# MSS_ETPWM3 register map
Vendor: Texas Instruments
Peripheral module from a debugger description file (folder radar).
Registers are 32-bit, read-write, no defined reset value unless marked. A register's access mark holds for its fields unless they carry their own. Offsets are as the file gives them; lines under a group give offsets from that group; [hi:lo] are bit positions; {n}, {i} and the like mark numbered series; 'fields as' and 'values as' point back to an identical list; <NAME> marks a mode.

## MSS_ETPWM3
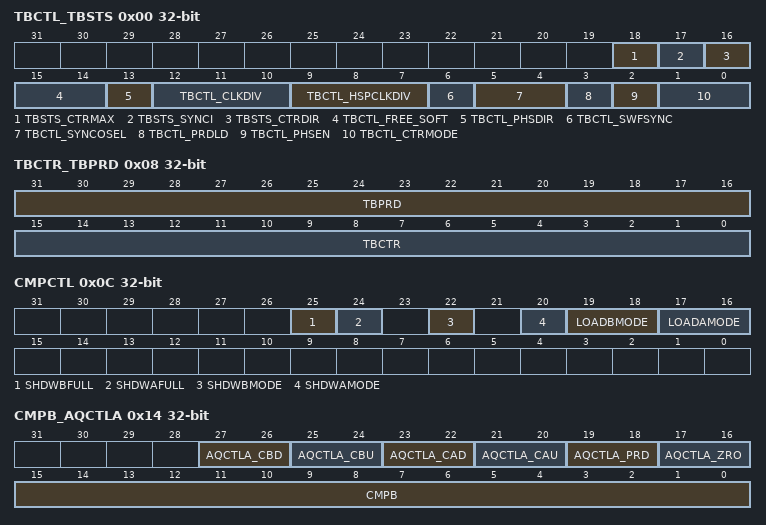
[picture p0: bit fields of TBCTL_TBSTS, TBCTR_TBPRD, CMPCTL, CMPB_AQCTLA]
0x00 TBCTL_TBSTS — Time-Base Control Register/ Status Register
  [18] TBSTS_CTRMAX — Time-Base Counter Max Latched Status Bit 0 Read: Indicates the time-base counter never reached its maximum value. Write: No effect. 1 Read: Indicates that the time-base counter reached the maximum value 0xFFFF. Write: Clears the latched event.
  [17] TBSTS_SYNCI — Input Synchronization Latched Status Bit 0 Read: Indicates no external synchronization event has occurred. Write: No effect. 1 Read: Indicates that an external synchronization event has occurred (EPWMxSYNCI). Write: Clears the latched event.
  [16] TBSTS_CTRDIR — Time-Base Counter Direction Status Bit. At reset, the counter is frozen; therefore, this bit has no meaning. To make this bit meaningful, you must first set the appropriate mode via TBCTL[CTRMODE]. 0 Time-Base Counter is currently counting down. 1 Time-Base Counter is currently counting up.
  [15:14] TBCTL_FREE_SOFT — Emulation Mode Bits. These bits select the behavior of the ePWM time-base counter during emulation events: 0 Stop after the next time-base counter increment or decrement 1h Stop when counter completes a whole cycle: • Up-count mode: stop when the time-base counter = period (TBCTR = TBPRD) • Down-count mode: stop when the time-base counter = 0x0000 (TBCTR = 0x0000) • Up-down-count mode: stop when the time-base counter = 0x0000 (TBCTR = 0x0000) 2h-3h Free run
  [13] TBCTL_PHSDIR — Phase Direction Bit. This bit is only used when the time-base counter is configured in the up-down-count mode. The PHSDIR bit indicates the direction the time-base counter (TBCTR) will count after a synchronization event occurs and a new phase value is loaded from the phase (TBPHS) register. This is irrespective of the direction of the counter before the synchronization event.. In the up-count and down-count modes this bit is ignored. 0 Count down after the synchronization event. 1 Count up after the synchronization event
  [12:10] TBCTL_CLKDIV — Time-base Clock Prescale Bits These bits determine part of the time-base clock prescale value. TBCLK = VCLK3 / (HSPCLKDIV � CLKDIV) 0 /1 (default on reset) 1h /2 2h /4 3h /8 4h /16 5h /32 6h /64 7h /128
  [9:7] TBCTL_HSPCLKDIV — High Speed Time-base Clock Prescale Bits. These bits determine part of the time-base clock prescale value: TBCLK = VCLK3 / (HSPCLKDIV � CLKDIV) 0 /1 1h /2 (default on reset) 2h /4 3h /6 4h /8 5h /10 6h /12 7h /14
  [6] TBCTL_SWFSYNC — Software Forced Synchronization Pulse 0 Writing a 0 has no effect and reads always return a 0. 1 Writing a 1 forces a one-time synchronization pulse to be generated. This event is ORed with the EPWMxSYNCI input of the ePWM module. SWFSYNC is valid (operates) only when EPWMxSYNCI is selected by SYNCOSEL = 00.
  [5:4] TBCTL_SYNCOSEL — Synchronization Output Select. These bits select the source of the EPWMxSYNCO signal. 0 EPWMxSYNC: 1h CTR = zero: Time-base counter equal to zero (TBCTR = 0x0000) 2h CTR = CMPB : Time-base counter equal to counter-compare B (TBCTR = CMPB) 3h Disable EPWMxSYNCO signal
  [3] TBCTL_PRDLD — Active Period Register Load From Shadow Register Select 0 The period register (TBPRD) is loaded from its shadow register when the time-base counter, TBCTR, is equal to zero. A write or read to the TBPRD register accesses the shadow register. 1 Load the TBPRD register immediately without using a shadow register. A write or read to the TBPRD register directly accesses the active register.
  [2] TBCTL_PHSEN — Counter Register Load From Phase Register Enable 0 Do not load the time-base counter (TBCTR) from the time-base phase register (TBPHS) 1 Load the time-base counter with the phase register when an EPWMxSYNCI input signal occurs or when a software synchronization is forced by the SWFSYNC bit, or when a digital compare sync event occurs.
  [1:0] TBCTL_CTRMODE — Counter Mode The time-base counter mode is normally configured once and not changed during normal operation. If you change the mode of the counter, the change will take effect at the next TBCLK edge and the current counter value shall increment or decrement from the value before the mode change. These bits set the time-base counter mode of operation as follows: 0 Up-count mode 1h Down-count mode 2h Up-down-count mode 3h Stop-freeze counter operation (default on reset)
0x04 TBPHS — Time-Base Phase Register
  [31:16] TBPHS — Time-Base Phase Register These bits set time-base counter phase of the selected ePWM relative to the time-base that is supplying the synchronization input signal. • If TBCTL[PHSEN] = 0, then the synchronization event is ignored and the time-base counter is not loaded with the phase. • If TBCTL[PHSEN] = 1, then the time-base counter (TBCTR) will be loaded with the phase (TBPHS) when a synchronization event occurs. The synchronization event can be initiated by the input synchronization signal (EPWMxSYNCI) or by a software forced synchronization.
0x08 TBCTR_TBPRD — Time-Base Counter Register/ Period Register
  [31:16] TBPRD — Time-Base Period Register These bits determine the period of the time-base counter. This sets the PWM frequency. Shadowing of this register is enabled and disabled by the TBCTL[PRDLD] bit. By default this register is shadowed. • If TBCTL[PRDLD] = 0, then the shadow is enabled and any write or read will automatically go to the shadow register. In this case, the active register will be loaded from the shadow register when the timebase counter equals zero. • If TBCTL[PRDLD] = 1, then the shadow is disabled and any write or read will go directly to the active register, that is the register actively controlling the hardware. • The active and shadow registers share the same memory map address.
  [15:0] TBCTR — Time-Base Counter Register Reading these bits gives the current time-base counter value. Writing to these bits sets the current time-base counter value. The update happens as soon as the write occurs; the write is NOT synchronized to the time-base clock (TBCLK) and the register is not shadowed.
0x0C CMPCTL — Counter-Compare Control Register
  [25] SHDWBFULL — Counter-compare B (CMPB) Shadow Register Full Status Flag This bit self clears once a load-strobe occurs. 0 CMPB shadow FIFO not full yet 1 Indicates the CMPB shadow FIFO is full; a CPU write will overwrite current shadow value.
  [24] SHDWAFULL — Counter-compare A (CMPA) Shadow Register Full Status Flag The flag bit is set when a 32-bit write to CMPA:CMPAHR register or a 16-bit write to CMPA register is made. A 16-bit write to CMPAHR register will not affect the flag. This bit self clears once a load-strobe occurs. 0 CMPA shadow FIFO not full yet 1 Indicates the CMPA shadow FIFO is full, a CPU write will overwrite the current shadow value
  [22] SHDWBMODE — Counter-compare B (CMPB) Register Operating Mode 0 Shadow mode. Operates as a double buffer. All writes via the CPU access the shadow register. 1 Immediate mode. Only the active compare B register is used. All writes and reads directly access the active register for immediate compare action.
  [20] SHDWAMODE — Counter-compare A (CMPA) Register Operating Mode 0 Shadow mode. Operates as a double buffer. All writes via the CPU access the shadow register. 1 Immediate mode. Only the active compare register is used. All writes and reads directly access the active register for immediate compare action
  [19:18] LOADBMODE — Active Counter-Compare B (CMPB) Load From Shadow Select Mode This bit has no effect in immediate mode (CMPCTL[SHDWBMODE] = 1). 0 Load on CTR = Zero: Time-base counter equal to zero (TBCTR = 0x0000) 1h Load on CTR = PRD: Time-base counter equal to period (TBCTR = TBPRD) 2h Load on either CTR = Zero or CTR = PRD 3h Freeze (no loads possible)
  [17:16] LOADAMODE — Active Counter-Compare A (CMPA) Load From Shadow Select Mode. This bit has no effect in immediate mode (CMPCTL[SHDWAMODE] = 1). 0 Load on CTR = Zero: Time-base counter equal to zero (TBCTR = 0x0000) 1h Load on CTR = PRD: Time-base counter equal to period (TBCTR = TBPRD) 2h Load on either CTR = Zero or CTR = PRD 3h Freeze (no loads possible)
0x10 CMPA — Counter-Compare A Register
  [31:16] CMPA — Counter-Compare A Register The value in the active CMPA register is continuously compared to the time-base counter (TBCTR). When the values are equal, the counter-compare module generates a "time-base counter equal to counter compare A" event. This event is sent to the action-qualifier where it is qualified and converted it into one or more actions. These actions can be applied to either the EPWMxA or the EPWMxB output depending on the configuration of the AQCTLA and AQCTLB registers. The actions that can be defined in the AQCTLA and AQCTLB registers include: • Do nothing; the event is ignored. • Clear: Pull the EPWMxA and/or EPWMxB signal low • Set: Pull the EPWMxA and/or EPWMxB signal high • Toggle the EPWMxA and/or EPWMxB signal Shadowing of this register is enabled and disabled by the CMPCTL[SHDWAMODE] bit. By default this register is shadowed. • If CMPCTL[SHDWAMODE] = 0, then the shadow is enabled and any write or read will automatically go to the shadow register. In this case, the CMPCTL[LOADAMODE] bit field determines which event will load the active register from the shadow register. • Before a write, the CMPCTL[SHDWAFULL] bit can be read to determine if the shadow register is currently full. • If CMPCTL[SHDWAMODE] = 1, then the shadow register is disabled and any write or read will go directly to the active register, that is the register actively controlling the hardware. • In either mode, the active and shadow registers share the same memory map address.
0x14 CMPB_AQCTLA — Counter-Compare B Register/ Action-Qualifier Control Register for Output A (EPWMxA)
  [27:26] AQCTLA_CBD — Action when the time-base counter equals the active CMPB register and the counter is decrementing. 0 Do nothing (action disabled) 1h Clear: force EPWMxA output low. 2h Set: force EPWMxA output high. 3h Toggle EPWMxA output: low output signal will be forced high, and a high signal will be forced low
  [25:24] AQCTLA_CBU — Action when the counter equals the active CMPB register and the counter is incrementing. 0 Do nothing (action disabled) 1h Clear: force EPWMxA output low. 2h Set: force EPWMxA output high. 3h Toggle EPWMxA output: low output signal will be forced high, and a high signal will be forced low
  [23:22] AQCTLA_CAD — Action when the counter equals the active CMPA register and the counter is decrementing. 0 Do nothing (action disabled) 1h Clear: force EPWMxA output low. 2h Set: force EPWMxA output high. 3h Toggle EPWMxA output: low output signal will be forced high, and a high signal will be forced low
  [21:20] AQCTLA_CAU — Action when the counter equals the active CMPA register and the counter is incrementing. 0 Do nothing (action disabled) 1h Clear: force EPWMxA output low. 2h Set: force EPWMxA output high. 3h Toggle EPWMxA output: low output signal will be forced high, and a high signal will be forced low
  [19:18] AQCTLA_PRD — Action when the counter equals the period. Note: By definition, in count up-down mode when the counter equals period the direction is defined as 0 or counting down. 0 Do nothing (action disabled) 1h Clear: force EPWMxA output low. 2h Set: force EPWMxA output high. 3h Toggle EPWMxA output: low output signal will be forced high, and a high signal will be forced low
  [17:16] AQCTLA_ZRO — Action when counter equals zero. Note: By definition, in count up-down mode when the counter equals 0 the direction is defined as 1 or counting up. 0 Do nothing (action disabled) 1h Clear: force EPWMxA output low. 2h Set: force EPWMxA output high. 3h Toggle EPWMxA output: low output signal will be forced high, and a high signal will be forced low
  [15:0] CMPB — The value in the active CMPB register is continuously compared to the time-base counter (TBCTR). When the values are equal, the counter-compare module generates a "time-base counter equal to counter compare B" event. This event is sent to the action-qualifier where it is qualified and converted it into one or more actions. These actions can be applied to either the EPWMxA or the EPWMxB output depending on the configuration of the AQCTLA and AQCTLB registers. The actions that can be defined in the AQCTLA and AQCTLB registers include: • Do nothing. event is ignored. • Clear: Pull the EPWMxA and/or EPWMxB signal low • Set: Pull the EPWMxA and/or EPWMxB signal high • Toggle the EPWMxA and/or EPWMxB signal Shadowing of this register is enabled and disabled by the CMPCTL[SHDWBMODE] bit. By default this register is shadowed. • If CMPCTL[SHDWBMODE] = 0, then the shadow is enabled and any write or read will automatically go to the shadow register. In this case, the CMPCTL[LOADBMODE] bit field determines which event will load the active register from the shadow register: • Before a write, the CMPCTL[SHDWBFULL] bit can be read to determine if the shadow register is currently full. • If CMPCTL[SHDWBMODE] = 1, then the shadow register is disabled and any write or read will go directly to the active register, that is the register actively controlling the hardware. • In either mode, the active and shadow registers share the same memory map address
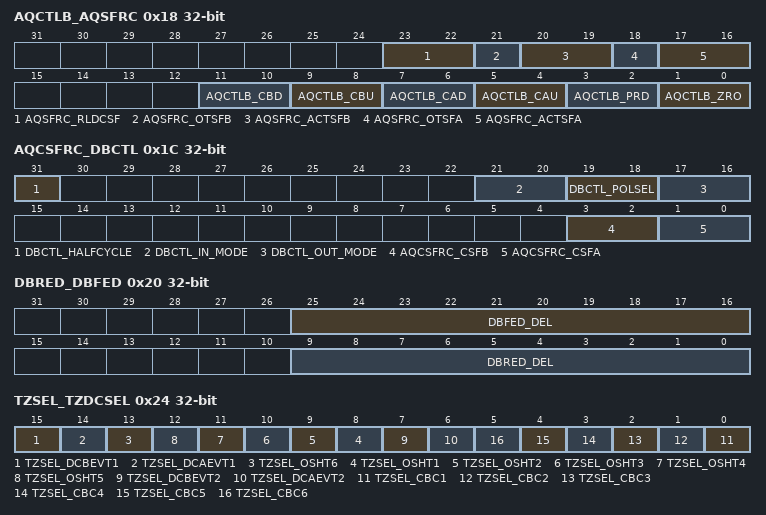
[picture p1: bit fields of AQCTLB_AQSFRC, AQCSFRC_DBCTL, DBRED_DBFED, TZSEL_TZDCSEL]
0x18 AQCTLB_AQSFRC — Action-Qualifier Control Register for Output B (EPWMxB)/ Action-Qualifier Software Force Register
  [23:22] AQSFRC_RLDCSF — AQCSFRC Active Register Reload From Shadow Options 0 Load on event counter equals zero 1h Load on event counter equals period 2h Load on event counter equals zero or counter equals period 3h Load immediately (the active register is directly accessed by the CPU and is not loaded from the shadow register).
  [21] AQSFRC_OTSFB — One-Time Software Forced Event on Output B 0 Writing a 0 has no effect. Always reads back a 0 This bit is auto cleared once a write to this register is complete (that is, a forced event is initiated.) This is a one-shot forced event. It can be overridden by another subsequent event on output B. 1 Initiates a single s/w forced event
  [20:19] AQSFRC_ACTSFB — Action when One-Time Software Force B Is invoked 0 Does nothing (action disabled) 1h Clear (low) 2h Set (high) 3h Toggle (Low -> High, High -> Low) Note: This action is not qualified by counter direction (CNT_dir)
  [18] AQSFRC_OTSFA — One-Time Software Forced Event on Output A 0 Writing a 0 has no effect. Always reads back a 0. This bit is auto cleared once a write to this register is complete (that is, a forced event is initiated). 1 Initiates a single software forced event
  [17:16] AQSFRC_ACTSFA — Action When One-Time Software Force A Is Invoked 0 Does nothing (action disabled) 1h Clear (low) 2h Set (high) 3h Toggle (Low → High, High → Low) Note: This action is not qualified by counter direction (CNT_dir)
  [11:10] AQCTLB_CBD — Action when the counter equals the active CMPB register and the counter is decrementing. 0 Do nothing (action disabled) 1h Clear: force EPWMxB output low. 2h Set: force EPWMxB output high. 3h Toggle EPWMxB output: low output signal will be forced high, and a high signal will be forced low
  [9:8] AQCTLB_CBU — Action when the counter equals the active CMPB register and the counter is incrementing. 0 Do nothing (action disabled) 1h Clear: force EPWMxB output low. 2h Set: force EPWMxB output high. 3h Toggle EPWMxB output: low output signal will be forced high, and a high signal will be forced low
  [7:6] AQCTLB_CAD — Action when the counter equals the active CMPA register and the counter is decrementing. 0 Do nothing (action disabled) 1h Clear: force EPWMxB output low. 2h Set: force EPWMxB output high. 3h Toggle EPWMxB output: low output signal will be forced high, and a high signal will be forced low
  [5:4] AQCTLB_CAU — Action when the counter equals the active CMPA register and the counter is incrementing. 0 Do nothing (action disabled) 1h Clear: force EPWMxB output low. 2h Set: force EPWMxB output high. 3h Toggle EPWMxB output: low output signal will be forced high, and a high signal will be forced low
  [3:2] AQCTLB_PRD — Action when the counter equals the period. Note: By definition, in count up-down mode when the counter equals period the direction is defined as 0 or counting down. 0 Do nothing (action disabled) 1h Clear: force EPWMxB output low. 2h Set: force EPWMxB output high. 3h Toggle EPWMxB output: low output signal will be forced high, and a high signal will be forced low
  [1:0] AQCTLB_ZRO — Action when counter equals zero. Note: By definition, in count up-down mode when the counter equals 0 the direction is defined as 1 or counting up. 0 Do nothing (action disabled) 1h Clear: force EPWMxB output low. 2h Set: force EPWMxB output high. 3h Toggle EPWMxB output: low output signal will be forced high, and a high signal will be forced low.
0x1C AQCSFRC_DBCTL — Dead-Band Generator Control Register/ Action-Qualifier Continuous S/W Force Register Set
  [31] DBCTL_HALFCYCLE — Half Cycle Clocking Enable Bit: 0 Full cycle clocking enabled. The dead-band counters are clocked at the TBCLK rate. 1 Half cycle clocking enabled. The dead-band counters are clocked at TBCLK � 2.
  [21:20] DBCTL_IN_MODE — Dead Band Input Mode Control Bit 5 controls the S5 switch and bit 4 controls the S4 switch shown in Figure 35-28. This allows you to select the input source to the falling-edge and rising-edge delay. To produce classical dead-band waveforms the default is EPWMxA In is the source for both falling and rising-edge delays. 0 EPWMxA In (from the action-qualifier) is the source for both falling-edge and rising-edge delay. 1h EPWMxB In (from the action-qualifier) is the source for rising-edge delayed signal. EPWMxA In (from the action-qualifier) is the source for falling-edge delayed signal. 2h EPWMxA In (from the action-qualifier) is the source for rising-edge delayed signal. EPWMxB In (from the action-qualifier) is the source for falling-edge delayed signal. 3h EPWMxB In (from the action-qualifier) is the source for both rising-edge delay and falling-edge delayed signal.
  [19:18] DBCTL_POLSEL — Polarity Select Control Bit 3 controls the S3 switch and bit 2 controls the S2 switch shown in Figure 35-28. This allows you to selectively invert one of the delayed signals before it is sent out of the dead-band submodule. The following descriptions correspond to classical upper/lower switch control as found in one leg of a digital motor control inverter. These assume that DBCTL[OUT_MODE] = 1,1 and DBCTL[IN_MODE] = 0,0. Other enhanced modes are also possible, but not regarded as typical usage modes. 0 Active high (AH) mode. Neither EPWMxA nor EPWMxB is inverted (default). 1h Active low complementary (ALC) mode. EPWMxA is inverted. 2h Active high complementary (AHC). EPWMxB is inverted. 3h Active low (AL) mode. Both EPWMxA and EPWMxB are inverted
  [17:16] DBCTL_OUT_MODE — Dead-band Output Mode Control Bit 1 controls the S1 switch and bit 0 controls the S0 switch shown in Figure 35-28. This allows you to selectively enable or bypass the dead-band generation for the falling-edge and rising-edge delay. 0 Dead-band generation is bypassed for both output signals. In this mode, both the EPWMxA and EPWMxB output signals from the action-qualifier are passed directly to the PWM-chopper submodule. In this mode, the POLSEL and IN_MODE bits have no effect. 1h Disable rising-edge delay. The EPWMxA signal from the action-qualifier is passed straight through to the EPWMxA input of the PWM-chopper submodule. The falling-edge delayed signal is seen on output EPWMxB. The input signal for the delay is determined by DBCTL[IN_MODE]. 2h The rising-edge delayed signal is seen on output EPWMxA. The input signal for the delay is determined by DBCTL[IN_MODE]. Disable falling-edge delay. The EPWMxB signal from the action-qualifier is passed straight through to the EPWMxB input of the PWM-chopper submodule. 3h Dead-band is fully enabled for both rising-edge delay on output EPWMxA and falling-edge delay on output EPWMxB. The input signal for the delay is determined by DBCTL[IN_MODE].
  [3:2] AQCSFRC_CSFB — Continuous Software Force on Output B In immediate mode, a continuous force takes effect on the next TBCLK edge. In shadow mode, a continuous force takes effect on the next TBCLK edge after a shadow load into the active register. To configure shadow mode, use AQSFRC[RLDCSF]. 0 Forcing disabled, that is, has no effect 1h Forces a continuous low on output B 2h Forces a continuous high on output B 3h Software forcing is disabled and has no effect
  [1:0] AQCSFRC_CSFA — Continuous Software Force on Output A In immediate mode, a continuous force takes effect on the next TBCLK edge. In shadow mode, a continuous force takes effect on the next TBCLK edge after a shadow load into the active register. 0 Forcing disabled, that is, has no effect 1h Forces a continuous low on output A 2h Forces a continuous high on output A 3h Software forcing is disabled and has no effect
0x20 DBRED_DBFED — Dead-Band Generator Rising Edge Delay Count Register/ Dead-Band Generator Falling Edge Delay Count Register
  [25:16] DBFED_DEL — Falling Edge Delay Count. 10-bit counter
  [9:0] DBRED_DEL — Rising Edge Delay Count. 10-bit counter
0x24 TZSEL_TZDCSEL — Trip Zone Digital Compare Select Register/ Trip-Zone Select Register
  [15] TZSEL_DCBEVT1 — Digital Compare Output B Event 1 Select 0 Disable DCBEVT1 as one-shot-trip source for this ePWM module. 1 Enable DCBEVT1 as one-shot-trip source for this ePWM module
  [14] TZSEL_DCAEVT1 — Digital Compare Output A Event 1 Select 0 Disable DCAEVT1 as one-shot-trip source for this ePWM module. 1 Enable DCAEVT1 as one-shot-trip source for this ePWM module
  [13] TZSEL_OSHT6 — Trip-zone 6 (TZ6) Select 0 Disable TZ6 as a one-shot trip source for this ePWM module. 1 Enable TZ6 as a one-shot trip source for this ePWM module
  [n+7] TZSEL_OSHT{n} (n=1..5) — Trip-zone {n} (TZ{n}) Select 0 Disable TZ{n} as a one-shot trip source for this ePWM module 1 Enable TZ{n} as a one-shot trip source for this ePWM module
  [7] TZSEL_DCBEVT2 — Digital Compare Output B Event 2 Select 0 Disable DCBEVT2 as a CBC trip source for this ePWM module 1 Enable DCBEVT2 as a CBC trip source for this ePWM module
  [6] TZSEL_DCAEVT2 — Digital Compare Output A Event 2 Select 0 Disable DCAEVT2 as a CBC trip source for this ePWM module 1 Enable DCAEVT2 as a CBC trip source for this ePWM module
  [n-1] TZSEL_CBC{n} (n=1..6) — Trip-zone {n} (TZ{n}) Select 0 Disable TZ{n} as a CBC trip source for this ePWM module 1 Enable TZ{n} as a CBC trip source for this ePWM module
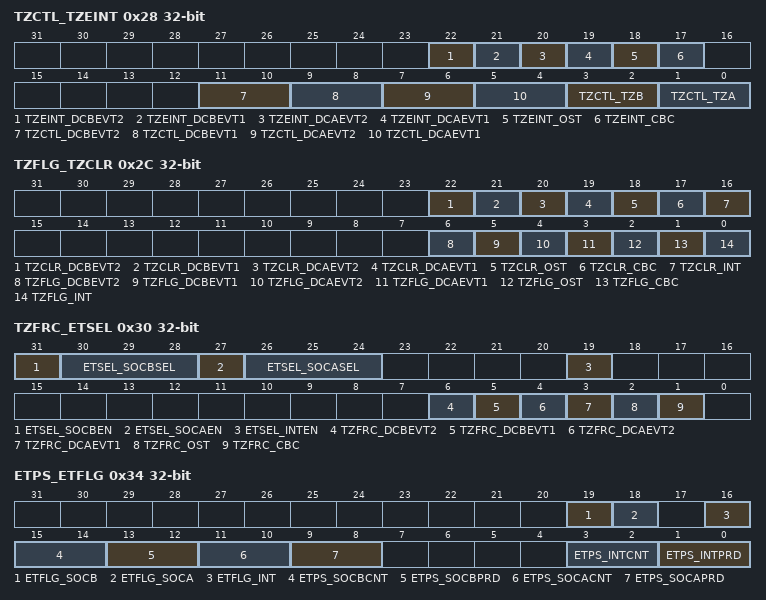
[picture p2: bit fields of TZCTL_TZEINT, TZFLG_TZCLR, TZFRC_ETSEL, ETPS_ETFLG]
0x28 TZCTL_TZEINT — Trip-Zone Control Register/ Trip-Zone Enable Interrupt Register
  [22] TZEINT_DCBEVT2 — Digital Comparator Output B Event 2 Interrupt Enable 0 Disabled 1 Enabled
  [21] TZEINT_DCBEVT1 — Digital Comparator Output B Event 1 Interrupt Enable 0 Disabled 1 Enabled
  [20] TZEINT_DCAEVT2 — Digital Comparator Output A Event 2 Interrupt Enable 0 Disabled 1 Enabled
  [19] TZEINT_DCAEVT1 — Digital Comparator Output A Event 1 Interrupt Enable 0 Disabled 1 Enabled
  [18] TZEINT_OST — Trip-zone One-Shot Interrupt Enable 0 Disable one-shot interrupt generation 1 Enable Interrupt generation; a one-shot trip event will cause a EPWMx_TZINT VIM interrupt
  [17] TZEINT_CBC — Trip-zone Cycle-by-Cycle Interrupt Enable 0 Disable cycle-by-cycle interrupt generation. 1 Enable interrupt generation; a cycle-by-cycle trip event will cause an EPWMx_TZINT VIM interrupt
  [11:10] TZCTL_DCBEVT2 — Digital Compare Output B Event 2 Action On EPWMxB: 0 High-impedance (EPWMxB = High-impedance state) 1h Force EPWMxB to a high state. 2h Force EPWMxB to a low state. 3h Do Nothing, trip action is disabled
  [9:8] TZCTL_DCBEVT1 — Digital Compare Output B Event 1 Action On EPWMxB: 0 High-impedance (EPWMxB = High-impedance state) 1h Force EPWMxB to a high state. 2h Force EPWMxB to a low state. 3h Do Nothing, trip action is disabled
  [7:6] TZCTL_DCAEVT2 — Digital Compare Output A Event 2 Action On EPWMxA: 0 High-impedance (EPWMxA = High-impedance state) 1h Force EPWMxA to a high state. 2h Force EPWMxA to a low state. 3h Do Nothing, trip action is disabled
  [5:4] TZCTL_DCAEVT1 — Digital Compare Output A Event 1 Action On EPWMxA: 0 High-impedance (EPWMxA = High-impedance state) 1h Force EPWMxA to a high state. 2h Force EPWMxA to a low state. 3h Do Nothing, trip action is disabled
  [3:2] TZCTL_TZB — When a trip event occurs the following action is taken on output EPWMxB. Which trip-zone pins can cause an event is defined in the TZSEL register. 0 High-impedance (EPWMxB = High-impedance state) 1h Force EPWMxB to a high state 2h Force EPWMxB to a low state 3h Do nothing, no action is taken on EPWMxB.
  [1:0] TZCTL_TZA — When a trip event occurs the following action is taken on output EPWMxA. Which trip-zone pins can cause an event is defined in the TZSEL register. 0 High-impedance (EPWMxA = High-impedance state) 1h Force EPWMxA to a high state 2h Force EPWMxA to a low state 3h Do nothing, no action is taken on EPWMxA
0x2C TZFLG_TZCLR — Trip-Zone Flag Register/ Trip-Zone Clear Register
  [22] TZCLR_DCBEVT2 — Clear Flag for Digital Compare Output B Event 2 0 Writing 0 has no effect. This bit always reads back 0. 1 Writing 1 clears the DCBEVT2 event trip condition.
  [21] TZCLR_DCBEVT1 — Clear Flag for Digital Compare Output B Event 1 0 Writing 0 has no effect. This bit always reads back 0. 1 Writing 1 clears the DCBEVT1 event trip condition
  [20] TZCLR_DCAEVT2 — Clear Flag for Digital Compare Output A Event 2 0 Writing 0 has no effect. This bit always reads back 0. 1 Writing 1 clears the DCAEVT2 event trip condition
  [19] TZCLR_DCAEVT1 — Clear Flag for Digital Compare Output A Event 1 0 Writing 0 has no effect. This bit always reads back 0. 1 Writing 1 clears the DCAEVT1 event trip condition.
  [18] TZCLR_OST — Clear Flag for One-Shot Trip (OST) Latch 0 Has no effect. Always reads back a 0. 1 Clears this Trip (set) condition.
  [17] TZCLR_CBC — Clear Flag for Cycle-By-Cycle (CBC) Trip Latch 0 Has no effect. Always reads back a 0. 1 Clears this Trip (set) condition.
  [16] TZCLR_INT — Global Interrupt Clear Flag 0 Has no effect. Always reads back a 0. 1 Clears the trip-interrupt flag for this ePWM module (TZFLG[INT]). NOTE: No further EPWMx_TZINT VIM interrupts will be generated until the flag is cleared. If the TZFLG[INT] bit is cleared and any of the other flag bits are set, then another interrupt pulse will be generated. Clearing all flag bits will prevent further interrupts.
  [6] TZFLG_DCBEVT2 — Latched Status Flag for Digital Compare Output B Event 2 0 Indicates no trip event has occurred on DCBEVT2 1 Indicates a trip event has occurred for the event defined for DCBEVT2
  [5] TZFLG_DCBEVT1 — Latched Status Flag for Digital Compare Output B Event 1 0 Indicates no trip event has occurred on DCBEVT1 1 Indicates a trip event has occurred for the event defined for DCBEVT1
  [4] TZFLG_DCAEVT2 — Latched Status Flag for Digital Compare Output A Event 2 0 Indicates no trip event has occurred on DCAEVT2 1 Indicates a trip event has occurred for the event defined for DCAEVT2
  [3] TZFLG_DCAEVT1 — Latched Status Flag for Digital Compare Output A Event 1 0 Indicates no trip event has occurred on DCAEVT1 1 Indicates a trip event has occurred for the event defined for DCAEVT1
  [2] TZFLG_OST — Latched Status Flag for A One-Shot Trip Event 0 No one-shot trip event has occurred. 1 Indicates a trip event has occurred on a pin selected as a one-shot trip source. This bit is cleared by writing the appropriate value to the TZCLR register
  [1] TZFLG_CBC — Latched Status Flag for Cycle-By-Cycle Trip Event 0 No cycle-by-cycle trip event has occurred. 1 Indicates a trip event has occurred on a signal selected as a cycle-by-cycle trip source. The TZFLG[CBC] bit will remain set until it is manually cleared by the user. If the cycle-by-cycle trip event is still present when the CBC bit is cleared, then CBC will be immediately set again. The specified condition on the signal is automatically cleared when the ePWM time-base counter reaches zero (TBCTR = 0x0000) if the trip condition is no longer present. The condition on the signal is only cleared when the TBCTR = 0x0000 no matter where in the cycle the CBC flag is cleared. This bit is cleared by writing the appropriate value to the TZCLR register
  [0] TZFLG_INT — Latched Trip Interrupt Status Flag 0 Indicates no interrupt has been generated. 1 Indicates an EPWMx_TZINT VIM interrupt was generated because of a trip condition. No further EPWMx_TZINT VIM interrupts will be generated until this flag is cleared. If the interrupt flag is cleared when either CBC or OST is set, then another interrupt pulse will be generated. Clearing all flag bits will prevent further interrupts. This bit is cleared by writing the appropriate value to the TZCLR register
0x30 TZFRC_ETSEL — Trip-Zone Force Register / Event-Trigger Selection Register
  [31] ETSEL_SOCBEN — Enable the ADC Start of Conversion B (EPWMxSOCB) Pulse 0 Disable EPWMxSOCB. 1 Enable EPWMxSOCB pulse
  [30:28] ETSEL_SOCBSEL — EPWMxSOCB Selection Options These bits determine when a EPWMxSOCB pulse will be generated. 0 Enable DCBEVT1.soc event 1h Enable event time-base counter equal to zero. (TBCTR = 0x0000) 2h Enable event time-base counter equal to period (TBCTR = TBPRD) 3h Enable event time-base counter equal to zero or period (TBCTR = 0x0000 or TBCTR = TBPRD). This mode is useful in up-down count mode. 4h Enable event time-base counter equal to CMPA when the timer is incrementing. 5h Enable event time-base counter equal to CMPA when the timer is decrementing. 6h Enable event: time-base counter equal to CMPB when the timer is incrementing. 7h Enable event: time-base counter equal to CMPB when the timer is decrementing
  [27] ETSEL_SOCAEN — Enable the ADC Start of Conversion A (EPWMxSOCA) Pulse 0 Disable EPWMxSOCA. 1 Enable EPWMxSOCA pulse.
  [26:24] ETSEL_SOCASEL — EPWMxSOCA Selection Options These bits determine when a EPWMxSOCA pulse will be generated. 0 Enable DCAEVT1.soc event 1h Enable event time-base counter equal to zero. (TBCTR = 0x0000) 2h Enable event time-base counter equal to period (TBCTR = TBPRD) 3h Enable event time-base counter equal to zero or period (TBCTR = 0x0000 or TBCTR = TBPRD). This mode is useful in up-down count mode. 4h Enable event time-base counter equal to CMPA when the timer is incrementing. 5h Enable event time-base counter equal to CMPA when the timer is decrementing. 6h Enable event: time-base counter equal to CMPB when the timer is incrementing. 7h Enable event: time-base counter equal to CMPB when the timer is decrementing
  [19] ETSEL_INTEN — Enable ePWM Interrupt (EPWMx_INT) Generation 0 Disable EPWMx_INT generation 1 Enable EPWMx_INT generation
  [6] TZFRC_DCBEVT2 — Force Flag for Digital Compare Output B Event 2 0 Writing 0 has no effect. This bit always reads back 0. 1 Writing 1 forces the DCBEVT2 event trip condition and sets the TZFLG[DCBEVT2] bit.
  [5] TZFRC_DCBEVT1 — Force Flag for Digital Compare Output B Event 1 0 Writing 0 has no effect. This bit always reads back 0. 1 Writing 1 forces the DCBEVT1 event trip condition and sets the TZFLG[DCBEVT1] bit
  [4] TZFRC_DCAEVT2 — Force Flag for Digital Compare Output A Event 2 0 Writing 0 has no effect. This bit always reads back 0. 1 Writing 1 forces the DCAEVT2 event trip condition and sets the TZFLG[DCAEVT2] bit
  [3] TZFRC_DCAEVT1 — Force Flag for Digital Compare Output A Event 1 0 Writing 0 has no effect. This bit always reads back 0 1 Writing 1 forces the DCAEVT1 event trip condition and sets the TZFLG[DCAEVT1] bit
  [2] TZFRC_OST — Force a One-Shot Trip Event via Software 0 Writing of 0 is ignored. Always reads back a 0. 1 Forces a one-shot trip event and sets the TZFLG[OST] bit
  [1] TZFRC_CBC — Force a Cycle-by-Cycle Trip Event via Software 0 Writing of 0 is ignored. Always reads back a 0. 1 Forces a cycle-by-cycle trip event and sets the TZFLG[CBC] bit.
0x34 ETPS_ETFLG — Event-Trigger Pre-Scale Register/ Event-Trigger Flag Register
  [19] ETFLG_SOCB — Latched ePWM ADC Start-of-Conversion B (EPWMxSOCB) Status Flag 0 Indicates no EPWMxSOCB event occurred 1 Indicates that a start of conversion pulse was generated on EPWMxSOCB. The EPWMxSOCB output will continue to be generated even if the flag bit is set.
  [18] ETFLG_SOCA — Latched ePWM ADC Start-of-Conversion A (EPWMxSOCA) Status Flag Unlike the ETFLG[INT] flag, the EPWMxSOCA output will continue to pulse even if the flag bit is set. 0 Indicates no event occurred 1 Indicates that a start of conversion pulse was generated on EPWMxSOCA. The EPWMxSOCA output will continue to be generated even if the flag bit is set
  [16] ETFLG_INT — Latched ePWM Interrupt (EPWMx_INT) Status Flag 0 Indicates no event occurred 1 Indicates that an ePWMx interrupt (EWPMx_INT) was generated. No further interrupts will be generated until the flag bit is cleared. Up to one interrupt can be pending while the ETFLG[INT] bit is still set. If an interrupt is pending, it will not be generated until after the ETFLG[INT] bit is cleared
  [15:14] ETPS_SOCBCNT — ePWM ADC Start-of-Conversion B Event (EPWMxSOCB) Counter Register These bits indicate how many selected ETSEL[SOCBSEL] events have occurred: 0 No events have occurred. 1h 1 event has occurred. 2h 2 events have occurred. 3h 3 events have occurred
  [13:12] ETPS_SOCBPRD — ePWM ADC Start-of-Conversion B Event (EPWMxSOCB) Period Select These bits determine how many selected ETSEL[SOCBSEL] events need to occur before an EPWMxSOCB pulse is generated. To be generated, the pulse must be enabled (ETSEL[SOCBEN] = 1). The SOCB pulse will be generated even if the status flag is set from a previous start of conversion (ETFLG[SOCB] = 1). Once the SOCB pulse is generated, the ETPS[SOCBCNT] bits will automatically be cleared. 0 Disable the SOCB event counter. No EPWMxSOCB pulse will be generated 1h Generate the EPWMxSOCB pulse on the first event: ETPS[SOCBCNT] = 0,1 2h Generate the EPWMxSOCB pulse on the second event: ETPS[SOCBCNT] = 1,0 3h Generate the EPWMxSOCB pulse on the third event: ETPS[SOCBCNT] = 1,1
  [11:10] ETPS_SOCACNT — ePWM ADC Start-of-Conversion A Event (EPWMxSOCA) Counter Register These bits indicate how many selected ETSEL[SOCASEL] events have occurred: 0 No events have occurred. 1h 1 event has occurred. 2h 2 events have occurred. 3h 3 events have occurred.
  [9:8] ETPS_SOCAPRD — ePWM ADC Start-of-Conversion A Event (EPWMxSOCA) Period Select These bits determine how many selected ETSEL[SOCASEL] events need to occur before an EPWMxSOCA pulse is generated. To be generated, the pulse must be enabled (ETSEL[SOCAEN] = 1). The SOCA pulse will be generated even if the status flag is set from a previous start of conversion (ETFLG[SOCA] = 1). Once the SOCA pulse is generated, the ETPS[SOCACNT] bits will automatically be cleared. 0 Disable the SOCA event counter. No EPWMxSOCA pulse will be generated 1h Generate the EPWMxSOCA pulse on the first event: ETPS[SOCACNT] = 0,1 2h Generate the EPWMxSOCA pulse on the second event: ETPS[SOCACNT] = 1,0 3h Generate the EPWMxSOCA pulse on the third event: ETPS[SOCACNT] = 1,1
  [3:2] ETPS_INTCNT — ePWM Interrupt Event (EPWMx_INT) Counter Register These bits indicate how many selected ETSEL[INTSEL] events have occurred. These bits are automatically cleared when an interrupt pulse is generated. If interrupts are disabled, ETSEL[INT] = 0 or the interrupt flag is set, ETFLG[INT] = 1, the counter will stop counting events when it reaches the period value ETPS[INTCNT] = ETPS[INTPRD]. 0 No events have occurred. 1h 1 event has occurred. 2h 2 events have occurred. 3h 3 events have occurred.
  [1:0] ETPS_INTPRD — ePWM Interrupt (EPWMx_INT) Period Select These bits determine how many selected ETSEL[INTSEL] events need to occur before an interrupt is generated. To be generated, the interrupt must be enabled (ETSEL[INT] = 1). If the interrupt status flag is set from a previous interrupt (ETFLG[INT] = 1) then no interrupt will be generated until the flag is cleared via the ETCLR[INT] bit. This allows for one interrupt to be pending while another is still being serviced. Once the interrupt is generated, the ETPS[INTCNT] bits will automatically be cleared. Writing a INTPRD value that is the same as the current counter value will trigger an interrupt if it is enabled and the status flag is clear. Writing a INTPRD value that is less than the current counter value will result in an undefined state. If a counter event occurs at the same instant as a new zero or non-zero INTPRD value is written, the counter is incremented. 0 Disable the interrupt event counter. No interrupt will be generated and ETFRC[INT] is ignored. 1h Generate an interrupt on the first event INTCNT = 01 (first event) 2h Generate interrupt on ETPS[INTCNT] = 1,0 (second event) 3h Generate interrupt on ETPS[INTCNT] = 1,1 (third event)
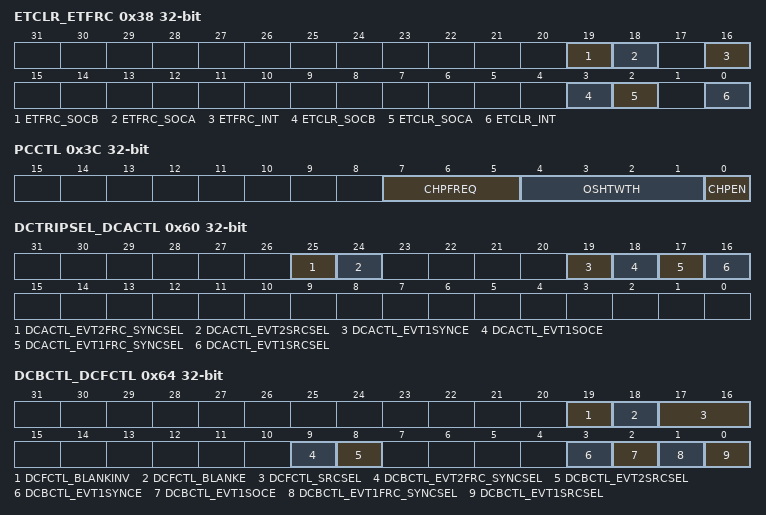
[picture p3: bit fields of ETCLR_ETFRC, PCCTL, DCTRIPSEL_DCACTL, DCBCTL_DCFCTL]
0x38 ETCLR_ETFRC — Event-Trigger Clear Register/ Event-Trigger Force Register
  [19] ETFRC_SOCB — SOCB Force Bit. The SOCB pulse will only be generated if the event is enabled in the ETSEL register. The ETFLG[SOCB] flag bit will be set regardless. 0 Has no effect. Always reads back a 0. 1 Generates a pulse on EPWMxSOCB and sets the SOCBFLG bit. This bit is used for test purposes
  [18] ETFRC_SOCA — SOCA Force Bit. The SOCA pulse will only be generated if the event is enabled in the ETSEL register. The ETFLG[SOCA] flag bit will be set regardless. 0 Writing 0 to this bit will be ignored. Always reads back a 0. 1 Generates a pulse on EPWMxSOCA and set the SOCAFLG bit. This bit is used for test purposes
  [16] ETFRC_INT — INT Force Bit. The interrupt will only be generated if the event is enabled in the ETSEL register. The INT flag bit will be set regardless. 0 Writing 0 to this bit will be ignored. Always reads back a 0. 1 Generates an interrupt on EPWMxINT and set the INT flag bit. This bit is used for test purposes
  [3] ETCLR_SOCB — ePWM ADC Start-of-Conversion B (EPWMxSOCB) Flag Clear Bit 0 Writing a 0 has no effect. Always reads back a 0 1 Clears the ETFLG[SOCB] flag bit
  [2] ETCLR_SOCA — ePWM ADC Start-of-Conversion A (EPWMxSOCA) Flag Clear Bit 0 Writing a 0 has no effect. Always reads back a 0 1 Clears the ETFLG[SOCA] flag bit
  [0] ETCLR_INT — ePWM Interrupt (EPWMx_INT) Flag Clear Bit 0 Writing a 0 has no effect. Always reads back a 0 1 Clears the ETFLG[INT] flag bit and enable further interrupts pulses to be generated
0x3C PCCTL — PWM-Chopper Control Register
  [7:5] CHPFREQ — Chopping Clock Frequency 0 Divide by 1 (no prescale, = 12.5 MHz at 100 MHz VCLK3) 1h Divide by 2 (6.25 MHz at 100 MHz VCLK3) 2h Divide by 3 (4.16 MHz at 100 MHz VCLK3) 3h Divide by 4 (3.12 MHz at 100 MHz VCLK3) 4h Divide by 5 (2.50 MHz at 100 MHz VCLK3) 5h Divide by 6 (2.08 MHz at 100 MHz VCLK3) 6h Divide by 7 (1.78 MHz at 100 MHz VCLK3) 7h Divide by 8 (1.56 MHz at 100 MHz VCLK3)
  [4:1] OSHTWTH — One-Shot Pulse Width 0 1 x VCLK3 / 8 wide ( = 80 nS at 100 MHz VCLK3) 1h 2 x VCLK3 / 8 wide ( = 160 nS at 100 MHz VCLK3) 2h 3 x VCLK3 / 8 wide ( = 240 nS at 100 MHz VCLK3) 3h 4 x VCLK3 / 8 wide ( = 320 nS at 100 MHz VCLK3) 4h 5 x VCLK3 / 8 wide ( = 400 nS at 100 MHz VCLK3) 5h 6 x VCLK3 / 8 wide ( = 480 nS at 100 MHz VCLK3) 6h 7 x VCLK3 / 8 wide ( = 560 nS at 100 MHz VCLK3) 7h 8 x VCLK3 / 8 wide ( = 640 nS at 100 MHz VCLK3) 8h 9 x VCLK3 / 8 wide ( = 720 nS at 100 MHz VCLK3) 9h 10 x VCLK3 / 8 wide ( = 800 nS at 100 MHz VCLK3) Ah 11 x VCLK3 / 8 wide ( = 880 nS at 100 MHz VCLK3) Bh 12 x VCLK3 / 8 wide ( = 960 nS at 100 MHz VCLK3) Ch 13 x VCLK3 / 8 wide ( = 1040 nS at 100 MHz VCLK3) Dh 14 x VCLK3 / 8 wide ( = 1120 nS at 100 MHz VCLK3) Eh 15 x VCLK3 / 8 wide ( = 1200 nS at 100 MHz VCLK3) Fh 16 x VCLK3 / 8 wide ( = 1280 nS at 100 MHz VCLK3)
  [0] CHPEN — PWM-chopping Enable 0 Disable (bypass) PWM chopping function 1 Enable chopping function
0x60 DCTRIPSEL_DCACTL — Digital Compare Trip Select Register/ Digital Compare A Control Register
  [25] DCACTL_EVT2FRC_SYNCSEL — DCAEVT2 Force Synchronization Signal Select 0 Source Is Synchronous Signal 1 Source Is Asynchronous Signal
  [24] DCACTL_EVT2SRCSEL — DCAEVT2 Source Signal Select 0 Source Is DCAEVT2 Signal 1 Source Is DCEVTFILT Signal
  [19] DCACTL_EVT1SYNCE — DCAEVT1 SYNC, Enable/Disable 0 SYNC Generation Disabled 1 SYNC Generation Enabled
  [18] DCACTL_EVT1SOCE — DCAEVT1 SOC, Enable/Disable 0 SOC Generation Disabled 1 SOC Generation Enabled
  [17] DCACTL_EVT1FRC_SYNCSEL — DCAEVT1 Force Synchronization Signal Select 0 Source Is Synchronous Signal 1 Source Is Asynchronous Signal
  [16] DCACTL_EVT1SRCSEL — DCAEVT1 Source Signal Select 0 Source Is DCAEVT1 Signal 1 Source Is DCEVTFILT Signal
0x64 DCBCTL_DCFCTL — Digital Compare B Control Register/ Digital Compare Filter Control Register
  [19] DCFCTL_BLANKINV — Blanking Window Inversion 0 Blanking window not inverted 1 Blanking window inverted
  [18] DCFCTL_BLANKE — Blanking Window Enable/Disable 0 Blanking window is disabled 1 Blanking window is enabled
  [17:16] DCFCTL_SRCSEL — Filter Block Signal Source Select 0 Source Is DCAEVT1 Signal 1h Source Is DCAEVT2 Signal 2h Source Is DCBEVT1 Signal 3h Source Is DCBEVT2 Signal
  [9] DCBCTL_EVT2FRC_SYNCSEL — DCBEVT2 Force Synchronization Signal Select 0 Source Is Synchronous Signal 1 Source Is Asynchronous Signal
  [8] DCBCTL_EVT2SRCSEL — DCBEVT2 Source Signal Select 0 Source Is DCBEVT2 Signal 1 Source Is DCEVTFILT Signal
  [3] DCBCTL_EVT1SYNCE — DCBEVT1 SYNC, Enable/Disable 0 SYNC Generation Disabled 1 SYNC Generation Enabled
  [2] DCBCTL_EVT1SOCE — DCBEVT1 SOC, Enable/Disable 0 SOC Generation Disabled 1 SOC Generation Enabled
  [1] DCBCTL_EVT1FRC_SYNCSEL — DCBEVT1 Force Synchronization Signal Select 0 Source Is Synchronous Signal 1 Source Is Asynchronous Signal
  [0] DCBCTL_EVT1SRCSEL — DCBEVT1 Source Signal Select 0 Source Is DCBEVT1 Signal 1 Source Is DCEVTFILT Signal
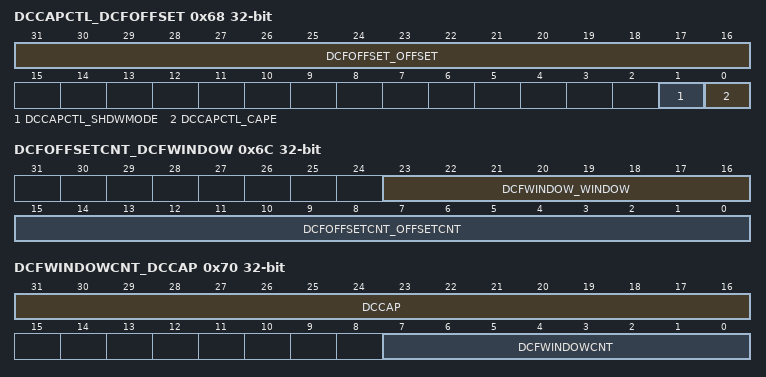
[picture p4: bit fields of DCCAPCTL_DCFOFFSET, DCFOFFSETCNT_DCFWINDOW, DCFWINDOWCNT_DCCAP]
0x68 DCCAPCTL_DCFOFFSET — Digital Compare Capture Control Register/ Digital Compare Filter Offset Register
  [31:16] DCFOFFSET_OFFSET — Blanking Window Offset These 16-bits specify the number of TBCLK cycles from the blanking window reference to the point when the blanking window is applied. The blanking window reference is either period or zero as defined by the DCFCTL[PULSESEL] bit. This offset register is shadowed and the active register is loaded at the reference point defined by DCFCTL[PULSESEL]. The offset counter is also initialized and begins to count down when the active register is loaded. When the counter expires, the blanking window is applied. If the blanking window is currently active, then the blanking window counter is restarted.
  [1] DCCAPCTL_SHDWMODE — TBCTR Counter Capture Shadow Select Mode 0 Enable shadow mode. The DCCAP active register is copied to shadow register on a TBCTR = TBPRD or TBCTR = zero event as defined by the DCFCTL[PULSESEL] bit. CPU reads of the DCCAP register will return the shadow register contents. 1 Active Mode. In this mode the shadow register is disabled. CPU reads from the DCCAP register will always return the active register contents
  [0] DCCAPCTL_CAPE — TBCTR Counter Capture Enable/Disable 0 Disable the time-base counter capture. 1 Enable the time-base counter capture.
0x6C DCFOFFSETCNT_DCFWINDOW — Digital Compare Filter Offset Counter Register/ Digital Compare Filter Window Register
  [23:16] DCFWINDOW_WINDOW — Blanking Window Width 0 No blanking window is generated. 1h-FFh Specifies the width of the blanking window in TBCLK cycles. The blanking window begins when the offset counter expires. When this occurs, the window counter is loaded and begins to count down. If the blanking window is currently active and the offset counter expires, the blanking window counter is restarted. The blanking window can cross a PWM period boundary.
  [15:0] DCFOFFSETCNT_OFFSETCNT — Blanking Offset Counter These 16-bits are read only and indicate the current value of the offset counter. The counter counts down to zero and then stops until it is re-loaded on the next period or zero event as defined by the DCFCTL[PULSESEL] bit. The offset counter is not affected by the free/soft emulation bits. That is, it will always continue to count down if the device is halted by a emulation stop.
0x70 DCFWINDOWCNT_DCCAP — Digital Compare Filter Window Counter Register/ Digital Compare Counter Capture Register
  [31:16] DCCAP — Digital Compare Time-Base Counter Capture To enable time-base counter capture, set the DCCAPCLT[CAPE] bit to 1. If enabled, reflects the value of the time-base counter (TBCTR) on the low to high edge transition of a filtered (DCEVTFLT) event. Further capture events are ignored until the next period or zero as selected by the DCFCTL[PULSESEL] bit. Shadowing of DCCAP is enabled and disabled by the DCCAPCTL[SHDWMODE] bit. By default this register is shadowed. • If DCCAPCTL[SHDWMODE] = 0, then the shadow is enabled. In this mode, the active register is copied to the shadow register on the TBCTR = TBPRD or TBCTR = zero as defined by the DCFCTL[PULSESEL] bit. CPU reads of this register will return the shadow register value. • If DCCAPCTL[SHDWMODE] = 1, then the shadow register is disabled. In this mode, CPU reads will return the active register value. The active and shadow registers share the same memory map address.
  [7:0] DCFWINDOWCNT — 0-FFh Blanking Window Counter These 8 bits are read only and indicate the current value of the window counter. The counter counts down to zero and then stops until it is re-loaded when the offset counter reaches zero again.
